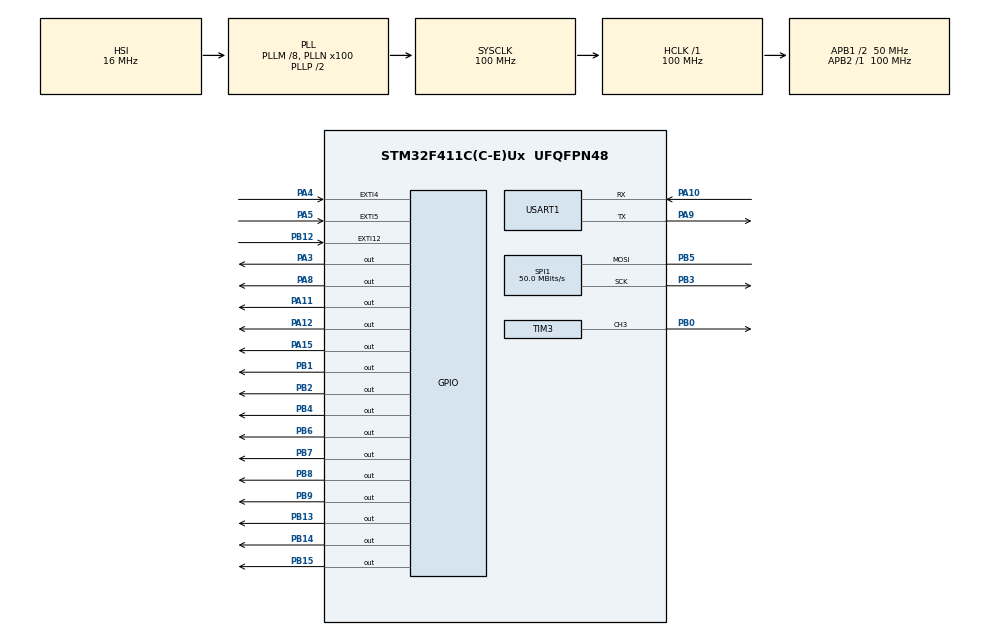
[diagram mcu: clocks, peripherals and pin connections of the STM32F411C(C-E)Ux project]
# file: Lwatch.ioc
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Dma.Request0=USART1_RX
Dma.Request1=USART1_TX
Dma.USART1_RX.0.Direction=DMA_PERIPH_TO_MEMORY
Dma.USART1_RX.0.FIFOMode=DMA_FIFOMODE_DISABLE
Dma.USART1_RX.0.Instance=DMA2_Stream2
Dma.USART1_RX.0.MemDataAlignment=DMA_MDATAALIGN_BYTE
Dma.USART1_RX.0.MemInc=DMA_MINC_ENABLE
Dma.USART1_RX.0.Mode=DMA_NORMAL
Dma.USART1_RX.0.PeriphDataAlignment=DMA_PDATAALIGN_BYTE
Dma.USART1_RX.0.PeriphInc=DMA_PINC_DISABLE
Dma.USART1_RX.0.Priority=DMA_PRIORITY_LOW
Dma.USART1_TX.1.Direction=DMA_MEMORY_TO_PERIPH
Dma.USART1_TX.1.FIFOMode=DMA_FIFOMODE_DISABLE
Dma.USART1_TX.1.Instance=DMA2_Stream7
Dma.USART1_TX.1.MemDataAlignment=DMA_MDATAALIGN_BYTE
Dma.USART1_TX.1.MemInc=DMA_MINC_ENABLE
Dma.USART1_TX.1.Mode=DMA_NORMAL
Dma.USART1_TX.1.PeriphDataAlignment=DMA_PDATAALIGN_BYTE
Dma.USART1_TX.1.PeriphInc=DMA_PINC_DISABLE
Dma.USART1_TX.1.Priority=DMA_PRIORITY_LOW
FREERTOS.Tasks01=defaultTask,24,128,StartDefaultTask,Default,NULL,Dynamic,NULL,NULL
IWDG.Prescaler=IWDG_PRESCALER_32
IWDG.Reload=4000
Mcu.Family=STM32F4
Mcu.Name=STM32F411C(C-E)Ux
Mcu.Package=UFQFPN48
NVIC.DMA2_Stream2_IRQn=true\:5\:0\:false\:false\:true\:true\:false\:true\:true
NVIC.DMA2_Stream7_IRQn=true\:5\:0\:false\:false\:true\:true\:false\:true\:true
NVIC.PriorityGroup=NVIC_PRIORITYGROUP_4
NVIC.TIM1_UP_TIM10_IRQn=true\:15\:0\:false\:false\:true\:false\:false\:true\:true
NVIC.TimeBase=TIM1_UP_TIM10_IRQn
NVIC.TimeBaseIP=TIM10
NVIC.USART1_IRQn=true\:5\:0\:false\:false\:true\:true\:true\:true\:true
PA10.Mode=Asynchronous
PA10.Signal=USART1_RX
PA11.GPIO_ModeDefaultOutputPP=GPIO_MODE_OUTPUT_OD
PA11.GPIO_PuPd=GPIO_NOPULL
PA11.Signal=GPIO_Output
PA12.Signal=GPIO_Output
PA13.Mode=Serial_Wire
PA13.Signal=SYS_JTMS-SWDIO
PA14.Mode=Serial_Wire
PA14.Signal=SYS_JTCK-SWCLK
PA15.Signal=GPIO_Output
PA3.Signal=GPIO_Output
PA4.Signal=GPXTI4
PA5.Signal=GPXTI5
PA8.Signal=GPIO_Output
PA9.Mode=Asynchronous
PA9.Signal=USART1_TX
PB0.Signal=S_TIM3_CH3
PB1.PinState=GPIO_PIN_SET
PB1.Signal=GPIO_Output
PB12.Signal=GPXTI12
PB13.GPIO_ModeDefaultOutputPP=GPIO_MODE_OUTPUT_OD
PB13.GPIO_PuPd=GPIO_NOPULL
PB13.Signal=GPIO_Output
PB14.Signal=GPIO_Output
PB15.Signal=GPIO_Output
PB2.Signal=GPIO_Output
PB3.Mode=Simplex_Bidirectional_Master
PB3.Signal=SPI1_SCK
PB4.GPIO_ModeDefaultOutputPP=GPIO_MODE_OUTPUT_OD
PB4.GPIO_PuPd=GPIO_NOPULL
PB4.Signal=GPIO_Output
PB5.Mode=Simplex_Bidirectional_Master
PB5.Signal=SPI1_MOSI
PB6.Signal=GPIO_Output
PB7.Signal=GPIO_Output
PB8.Signal=GPIO_Output
PB9.Signal=GPIO_Output
PC14-OSC32_IN.Mode=LSE-External-Oscillator
PC14-OSC32_IN.Signal=RCC_OSC32_IN
PC15-OSC32_OUT.Mode=LSE-External-Oscillator
PC15-OSC32_OUT.Signal=RCC_OSC32_OUT
ProjectManager.HeapSize=0x200
ProjectManager.StackSize=0x400
ProjectManager.TargetToolchain=MDK-ARM V5.32
RCC.48MHZClocksFreq_Value=50000000
RCC.AHBFreq_Value=100000000
RCC.APB1CLKDivider=RCC_HCLK_DIV2
RCC.APB1Freq_Value=50000000
RCC.APB1TimFreq_Value=100000000
RCC.APB2Freq_Value=100000000
RCC.APB2TimFreq_Value=100000000
RCC.CortexFreq_Value=100000000
RCC.HCLKFreq_Value=100000000
RCC.HSE_VALUE=25000000
RCC.HSI_VALUE=16000000
RCC.PLLM=8
RCC.PLLN=100
RCC.SYSCLKFreq_VALUE=100000000
RCC.SYSCLKSource=RCC_SYSCLKSOURCE_PLLCLK
RCC.VCOOutputFreq_Value=200000000
SH.S_TIM3_CH3.0=TIM3_CH3,PWM Generation3 CH3
SPI1.CalculateBaudRate=50.0 MBits/s
SPI1.Direction=SPI_DIRECTION_1LINE
SPI1.Mode=SPI_MODE_MASTER
SPI1.VirtualType=VM_MASTER
TIM3.Channel-PWM\ Generation3\ CH3=TIM_CHANNEL_3
TIM3.Prescaler=100
USART1.VirtualMode=VM_ASYNC
VP_FREERTOS_VS_CMSIS_V2.Mode=CMSIS_V2
VP_IWDG_VS_IWDG.Mode=IWDG_Activate
VP_SYS_VS_tim10.Mode=TIM10
board=custom

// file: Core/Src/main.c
/* USER CODE BEGIN Header */
/**
  ******************************************************************************
  * @file           : main.c
  * @brief          : Main program body
  ******************************************************************************
  * @attention
  *
  * Copyright (c) 2025 STMicroelectronics.
  * All rights reserved.
  *
  * This software is licensed under terms that can be found in the LICENSE file
  * in the root directory of this software component.
  * If no LICENSE file comes with this software, it is provided AS-IS.
  *
  ******************************************************************************
  */
/* USER CODE END Header */
#include "main.h"
#include "cmsis_os.h"
#include "dma.h"
#include "iwdg.h"
#include "spi.h"
#include "tim.h"
#include "usart.h"
#include "gpio.h"

/* USER CODE BEGIN Includes */
#include "drv_base.h"
#include <stdio.h>
#include "app.h"

/* USER CODE END Includes */

void SystemClock_Config(void);
void MX_FREERTOS_Init(void);

int main(void)
{

  /* MCU Configuration--------------------------------------------------------*/

  /* Reset of all peripherals, Initializes the Flash interface and the Systick. */
  HAL_Init();

  /* Configure the system clock */
  SystemClock_Config();

  /* Initialize all configured peripherals */
  MX_GPIO_Init();
  MX_DMA_Init();
  //MX_IWDG_Init();
  MX_SPI1_Init();
  MX_TIM3_Init();
  MX_USART1_UART_Init();
  /* USER CODE BEGIN 2 */
  drv_base_init();
  app_init();
  /* USER CODE END 2 */

  /* Init scheduler */
  // osKernelInitialize();  /* Call init function for freertos objects (in cmsis_os2.c) */
  // MX_FREERTOS_Init();

  /* Start scheduler */
  //osKernelStart();

  /* We should never get here as control is now taken by the scheduler */

  /* Infinite loop */
  /* USER CODE BEGIN WHILE */
  while (1)
  {
    app_run();
    /* USER CODE END WHILE */

  }
}

void SystemClock_Config(void)
{
  RCC_OscInitTypeDef RCC_OscInitStruct = {0};
  RCC_ClkInitTypeDef RCC_ClkInitStruct = {0};

  /** Configure the main internal regulator output voltage
  */
  __HAL_RCC_PWR_CLK_ENABLE();
  __HAL_PWR_VOLTAGESCALING_CONFIG(PWR_REGULATOR_VOLTAGE_SCALE1);

  /** Initializes the RCC Oscillators according to the specified parameters
  * in the RCC_OscInitTypeDef structure.
  */
  RCC_OscInitStruct.OscillatorType = RCC_OSCILLATORTYPE_HSI|RCC_OSCILLATORTYPE_LSI;
  RCC_OscInitStruct.HSIState = RCC_HSI_ON;
  RCC_OscInitStruct.HSICalibrationValue = RCC_HSICALIBRATION_DEFAULT;
  RCC_OscInitStruct.LSIState = RCC_LSI_ON;
  RCC_OscInitStruct.PLL.PLLState = RCC_PLL_ON;
  RCC_OscInitStruct.PLL.PLLSource = RCC_PLLSOURCE_HSI;
  RCC_OscInitStruct.PLL.PLLM = 8;
  RCC_OscInitStruct.PLL.PLLN = 100;
  RCC_OscInitStruct.PLL.PLLP = RCC_PLLP_DIV2;
  RCC_OscInitStruct.PLL.PLLQ = 4;
  if (HAL_RCC_OscConfig(&RCC_OscInitStruct) != HAL_OK)
  {
    Error_Handler();
  }

  /** Initializes the CPU, AHB and APB buses clocks
  */
  RCC_ClkInitStruct.ClockType = RCC_CLOCKTYPE_HCLK|RCC_CLOCKTYPE_SYSCLK
                              |RCC_CLOCKTYPE_PCLK1|RCC_CLOCKTYPE_PCLK2;
  RCC_ClkInitStruct.SYSCLKSource = RCC_SYSCLKSOURCE_PLLCLK;
  RCC_ClkInitStruct.AHBCLKDivider = RCC_SYSCLK_DIV1;
  RCC_ClkInitStruct.APB1CLKDivider = RCC_HCLK_DIV2;
  RCC_ClkInitStruct.APB2CLKDivider = RCC_HCLK_DIV1;

  if (HAL_RCC_ClockConfig(&RCC_ClkInitStruct, FLASH_LATENCY_3) != HAL_OK)
  {
    Error_Handler();
  }

}

void HAL_TIM_PeriodElapsedCallback(TIM_HandleTypeDef *htim)
{
  if (htim->Instance == TIM10)
  {
    HAL_IncTick();
  }
}

void Error_Handler(void)
{
  /* USER CODE BEGIN Error_Handler_Debug */
  /* User can add his own implementation to report the HAL error return state */
  __disable_irq();
  while (1)
  {
    printf("Error\n");
  }
  /* USER CODE END Error_Handler_Debug */
}
